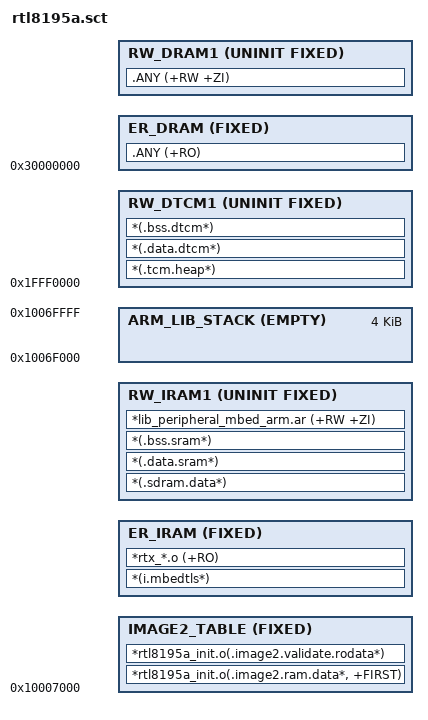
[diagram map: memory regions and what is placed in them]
; Realtek Semiconductor Corp.
;
; RTL8195A ARMCC Scatter File
;
; MEMORY
; {
;   SRAM (rwx)   : ORIGIN = 0x10007000, LENGTH = 0x00070000 - 0x00007000
;   DTCM (rw-)   : ORIGIN = 0x1FFF0000, LENGTH = 0x00010000
;   DRAM (rwx)   : ORIGIN = 0x30000000, LENGTH = 2M
; }

LR_IRAM 0x10007000 (0x70000 - 0x7000) {

  IMAGE2_TABLE 0x10007000 FIXED {
    *rtl8195a_init.o(.image2.ram.data*, +FIRST)
    *rtl8195a_init.o(.image2.validate.rodata*)
  }

  ER_IRAM +0 FIXED {
    *(i.mbedtls*)
    *rtx_*.o (+RO)
  }

  RW_IRAM1 +0 UNINIT FIXED {
    *(.sdram.data*)
    *(.data.sram*)
    *(.bss.sram*)
    *lib_peripheral_mbed_arm.ar (+RW +ZI)
  }

  ARM_LIB_STACK (0x10070000 - 0x1000) EMPTY 0x1000 {
  }
}

LR_DTCM 0x1FFF0000 0x10000 {

  RW_DTCM1 +0 UNINIT FIXED {
    *(.tcm.heap*)
    *(.data.dtcm*)
    *(.bss.dtcm*)
  }
}

LR_DRAM 0x30000000 0x200000 {

  ER_DRAM +0 FIXED {
    .ANY (+RO)
  }

  RW_DRAM1 +0 UNINIT FIXED {
    .ANY (+RW +ZI)
  }
}
